# STM32WB35_CM4 register map
File version: 1.3-IAR
CPU: CM4 r0p1, little endian, MPU, FPU, 4 interrupt priority bits
Registers are 32-bit, read-write, reset 0x0 unless marked. A register's access mark holds for its fields unless they carry their own. Offsets are from the block's base; [hi:lo] are bit positions; {n}, {i} and the like mark numbered series.

## GPIOA — General-purpose I/Os
Base 0x48000000
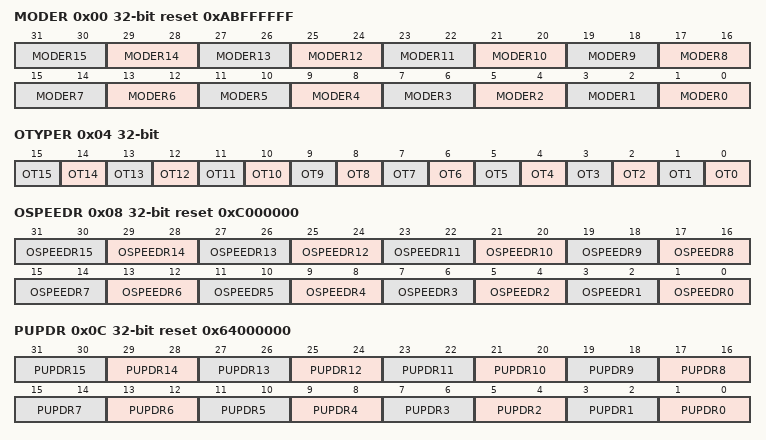
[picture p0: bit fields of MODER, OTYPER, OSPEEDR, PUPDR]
0x00 MODER reset 0xABFFFFFF — GPIO port mode register
  [2n+1:2n] MODER{n} (n=0..15) — Port x configuration bits (y = 0..15)
0x04 OTYPER — GPIO port output type register
  [n] OT{n} (n=0..15) — Port x configuration bits (y = 0..15)
0x08 OSPEEDR reset 0xC000000 — GPIO port output speed register
  [2n+1:2n] OSPEEDR{n} (n=0..15) — Port x configuration bits (y = 0..15)
0x0C PUPDR reset 0x64000000 — GPIO port pull-up/pull-down register
  [2n+1:2n] PUPDR{n} (n=0..15) — Port x configuration bits (y = 0..15)
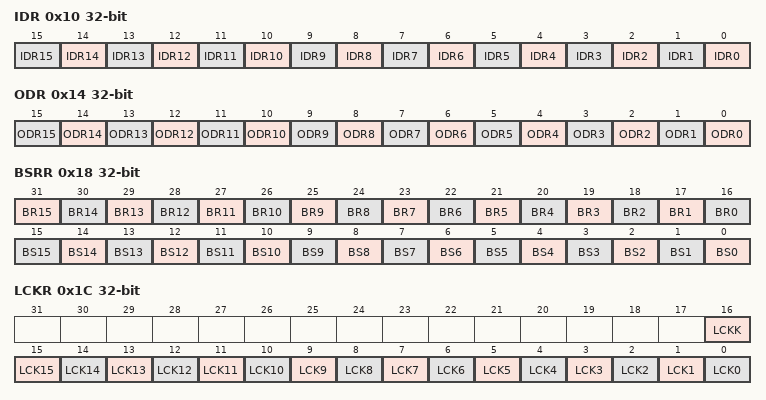
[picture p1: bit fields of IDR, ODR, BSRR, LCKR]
0x10 IDR ro — GPIO port input data register
  [n] IDR{n} (n=0..15) — Port input data (y = 0..15)
0x14 ODR — GPIO port output data register
  [n] ODR{n} (n=0..15) — Port output data (y = 0..15)
0x18 BSRR wo — GPIO port bit set/reset register
  [n+16] BR{n} (n=1..15) — Port x reset bit y (y = 0..15)
  [16] BR0 — Port x set bit y (y= 0..15)
  [n] BS{n} (n=0..15) — Port x set bit y (y= 0..15)
0x1C LCKR — GPIO port configuration lock register
  [16] LCKK — Port x lock bit y (y= 0..15)
  [n] LCK{n} (n=0..15) — Port x lock bit y (y= 0..15)
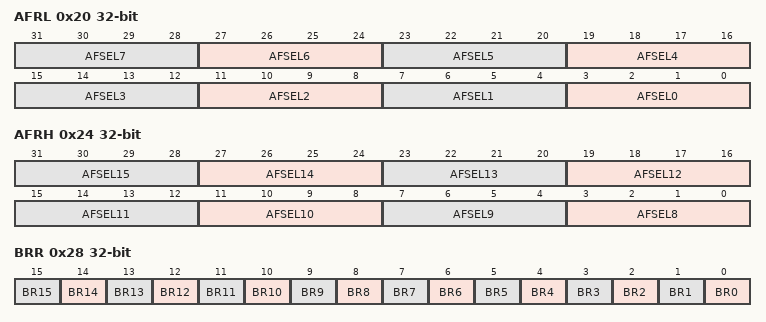
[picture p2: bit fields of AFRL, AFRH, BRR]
0x20 AFRL — GPIO alternate function low register
  [4n+3:4n] AFSEL{n} (n=0..7) — Alternate function selection for port x bit y (y = 0..7)
0x24 AFRH — GPIO alternate function high register
  [4n-29:4n-32] AFSEL{n} (n=8..15) — Alternate function selection for port x bit y (y = 8..15)
0x28 BRR wo — port bit reset register
  [n] BR{n} (n=0..15) — Port Reset bit

## GPIOB — General-purpose I/Os
Base 0x48000400
Registers as GPIOA; these are added or differ:
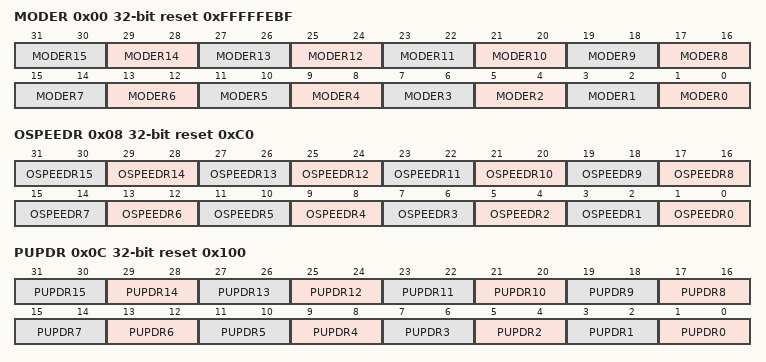
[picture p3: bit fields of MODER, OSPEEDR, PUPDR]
0x00 MODER reset 0xFFFFFEBF — GPIO port mode register
  [2n+1:2n] MODER{n} (n=0..15) — Port x configuration bits (y = 0..15)
0x08 OSPEEDR reset 0xC0 — GPIO port output speed register
  [2n+1:2n] OSPEEDR{n} (n=0..15) — Port x configuration bits (y = 0..15)
0x0C PUPDR reset 0x100 — GPIO port pull-up/pull-down register
  [2n+1:2n] PUPDR{n} (n=0..15) — Port x configuration bits (y = 0..15)

## GPIOC — General-purpose I/Os
Base 0x48000800
Registers as GPIOB; these are added or differ:
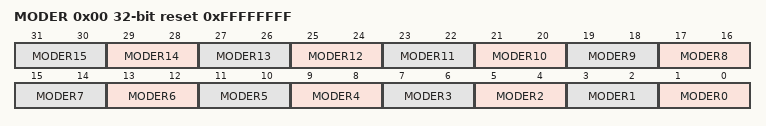
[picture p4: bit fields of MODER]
0x00 MODER reset 0xFFFFFFFF — GPIO port mode register
  [2n+1:2n] MODER{n} (n=0..15) — Port x configuration bits (y = 0..15)

## GPIOE — General-purpose I/Os
Base 0x48001000
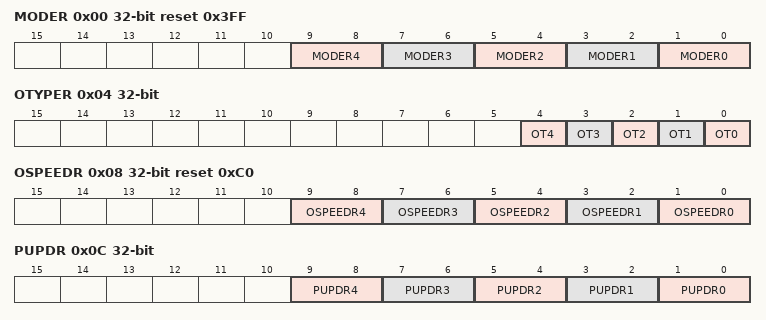
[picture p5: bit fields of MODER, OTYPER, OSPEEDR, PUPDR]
0x00 MODER reset 0x3FF — GPIO port mode register
  [2n+1:2n] MODER{n} (n=0..4) — Port x configuration bits (y = 0..15)
0x04 OTYPER — GPIO port output type register
  [n] OT{n} (n=0..4) — Port x configuration bits (y = 0..15)
0x08 OSPEEDR reset 0xC0 — GPIO port output speed register
  [2n+1:2n] OSPEEDR{n} (n=0..4) — Port x configuration bits (y = 0..15)
0x0C PUPDR — GPIO port pull-up/pull-down register
  [2n+1:2n] PUPDR{n} (n=0..4) — Port x configuration bits (y = 0..15)
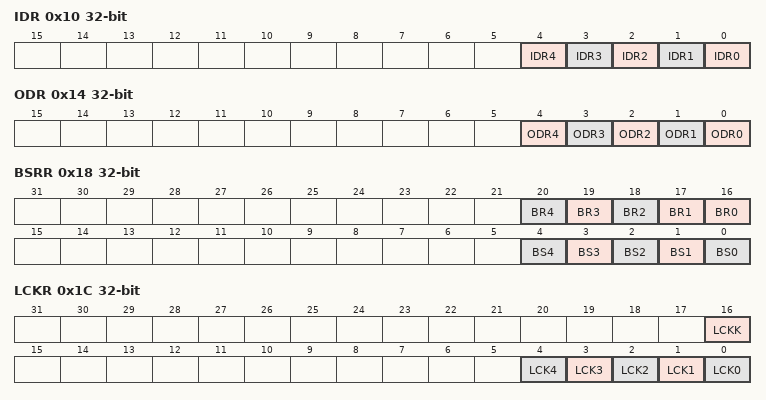
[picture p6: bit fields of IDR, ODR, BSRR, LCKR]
0x10 IDR ro — GPIO port input data register
  [n] IDR{n} (n=0..4) — Port input data (y = 0..15)
0x14 ODR — GPIO port output data register
  [n] ODR{n} (n=0..4) — Port output data (y = 0..15)
0x18 BSRR wo — GPIO port bit set/reset register
  [n+16] BR{n} (n=1..4) — Port x reset bit y (y = 0..15)
  [16] BR0 — Port x set bit y (y= 0..15)
  [n] BS{n} (n=0..4) — Port x set bit y (y= 0..15)
0x1C LCKR — GPIO port configuration lock register
  [16] LCKK — Port x lock bit y (y= 0..15)
  [n] LCK{n} (n=0..4) — Port x lock bit y (y= 0..15)
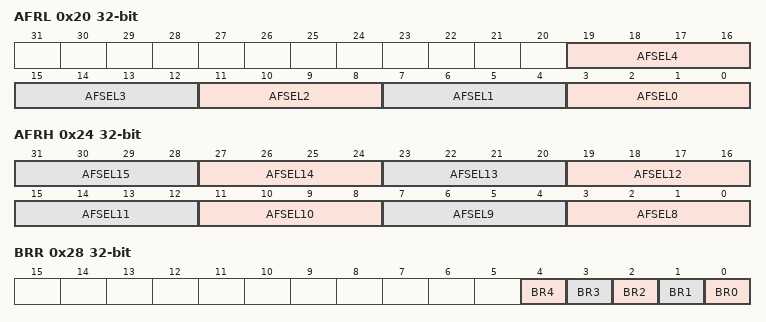
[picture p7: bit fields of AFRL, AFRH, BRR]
0x20 AFRL — GPIO alternate function low register
  [4n+3:4n] AFSEL{n} (n=0..4) — Alternate function selection for port x bit y (y = 0..7)
0x24 AFRH — GPIO alternate function high register
  [4n-29:4n-32] AFSEL{n} (n=8..15) — Alternate function selection for port x bit y (y = 8..15)
0x28 BRR wo — port bit reset register
  [n] BR{n} (n=0..4) — Port Reset bit

## GPIOH — General-purpose I/Os
Base 0x48001C00
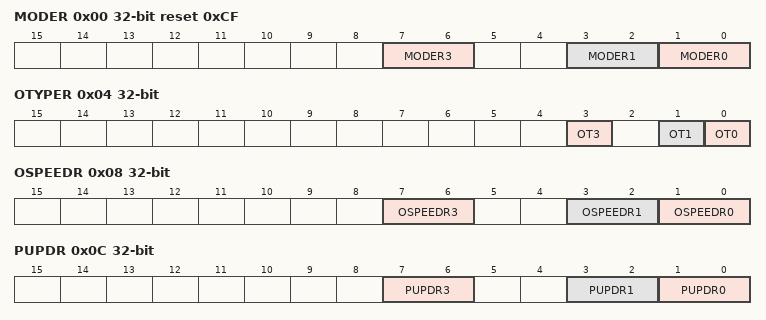
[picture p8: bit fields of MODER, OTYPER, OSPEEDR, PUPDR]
0x00 MODER reset 0xCF — GPIO port mode register
  [7:6] MODER3 — Port x configuration bits (y = 0..15)
  [3:2] MODER1 — Port x configuration bits (y = 0..15)
  [1:0] MODER0 — Port x configuration bits (y = 0..15)
0x04 OTYPER — GPIO port output type register
  [3] OT3 — Port x configuration bits (y = 0..15)
  [1] OT1 — Port x configuration bits (y = 0..15)
  [0] OT0 — Port x configuration bits (y = 0..15)
0x08 OSPEEDR — GPIO port output speed register
  [7:6] OSPEEDR3 — Port x configuration bits (y = 0..15)
  [3:2] OSPEEDR1 — Port x configuration bits (y = 0..15)
  [1:0] OSPEEDR0 — Port x configuration bits (y = 0..15)
0x0C PUPDR — GPIO port pull-up/pull-down register
  [7:6] PUPDR3 — Port x configuration bits (y = 0..15)
  [3:2] PUPDR1 — Port x configuration bits (y = 0..15)
  [1:0] PUPDR0 — Port x configuration bits (y = 0..15)
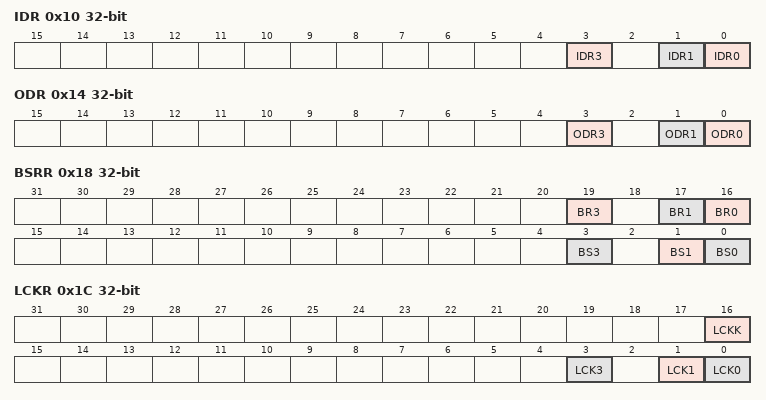
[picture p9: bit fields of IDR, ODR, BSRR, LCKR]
0x10 IDR ro — GPIO port input data register
  [3] IDR3 — Port input data (y = 0..15)
  [1] IDR1 — Port input data (y = 0..15)
  [0] IDR0 — Port input data (y = 0..15)
0x14 ODR — GPIO port output data register
  [3] ODR3 — Port output data (y = 0..15)
  [1] ODR1 — Port output data (y = 0..15)
  [0] ODR0 — Port output data (y = 0..15)
0x18 BSRR wo — GPIO port bit set/reset register
  [19] BR3 — Port x reset bit y (y = 0..15)
  [17] BR1 — Port x reset bit y (y = 0..15)
  [16] BR0 — Port x set bit y (y= 0..15)
  [3] BS3 — Port x set bit y (y= 0..15)
  [1] BS1 — Port x set bit y (y= 0..15)
  [0] BS0 — Port x set bit y (y= 0..15)
0x1C LCKR — GPIO port configuration lock register
  [16] LCKK — Port x lock bit y (y= 0..15)
  [3] LCK3 — Port x lock bit y (y= 0..15)
  [1] LCK1 — Port x lock bit y (y= 0..15)
  [0] LCK0 — Port x lock bit y (y= 0..15)
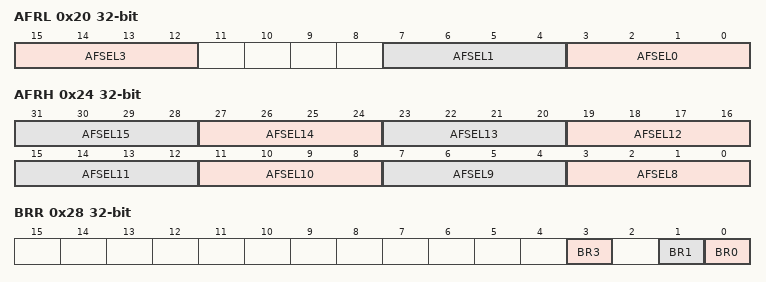
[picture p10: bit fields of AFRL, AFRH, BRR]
0x20 AFRL — GPIO alternate function low register
  [15:12] AFSEL3 — Alternate function selection for port x bit y (y = 0..7)
  [7:4] AFSEL1 — Alternate function selection for port x bit y (y = 0..7)
  [3:0] AFSEL0 — Alternate function selection for port x bit y (y = 0..7)
0x24 AFRH — GPIO alternate function high register
  [4n-29:4n-32] AFSEL{n} (n=8..15) — Alternate function selection for port x bit y (y = 8..15)
0x28 BRR wo — port bit reset register
  [3] BR3 — Port Reset bit
  [1] BR1 — Port Reset bit
  [0] BR0 — Port Reset bit
